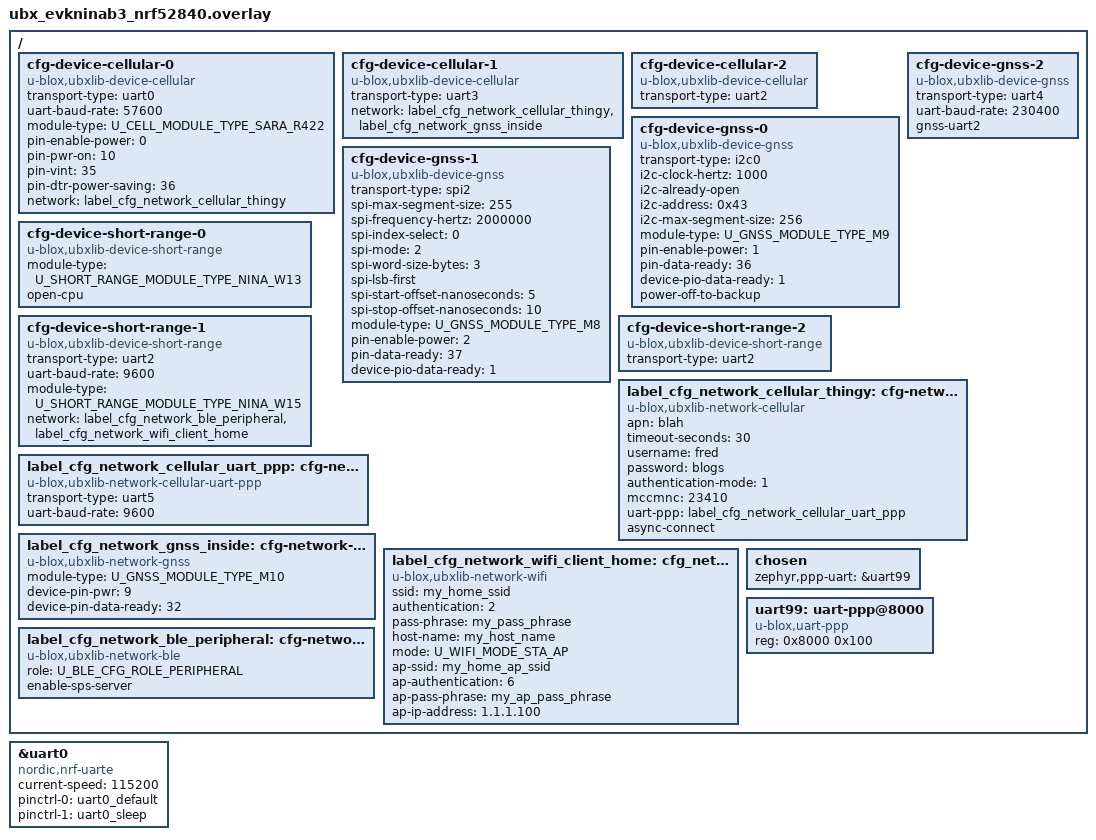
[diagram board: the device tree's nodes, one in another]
/* This configuration is used only to test setting ubxlib device and network configurations through
 * the device tree, it does not represent any real/useful settings.  The values here are checked
 * by the test zephyrPortBoardCfgBasic(); if you change a value here you must also change that test. */

/* For real settings, refer to the file of the same name in the boards/arm directory of Zephyr. */

/ {
    cfg-device-cellular-0 {
        compatible = "u-blox,ubxlib-device-cellular";
        status = "okay";
        transport-type = "uart0";
        uart-baud-rate = <57600>;
        module-type = "U_CELL_MODULE_TYPE_SARA_R422";
        pin-enable-power = <0>;
        pin-pwr-on = <10>;
        pin-vint = <35>;
        pin-dtr-power-saving = <36>;
        network = <&label_cfg_network_cellular_thingy>;
    };
    cfg-device-cellular-1 {
        compatible = "u-blox,ubxlib-device-cellular";
        status = "okay";
        transport-type = "uart3";
        network = <&label_cfg_network_cellular_thingy &label_cfg_network_gnss_inside>;
    };
    cfg-device-cellular-2 {
        compatible = "u-blox,ubxlib-device-cellular";
        status = "okay";
        transport-type = "uart2";
    };
    cfg-device-gnss-0 {
        compatible = "u-blox,ubxlib-device-gnss";
        status = "okay";
        transport-type = "i2c0";
        i2c-clock-hertz = <1000>;
        i2c-already-open;
        i2c-address = <0x43>;
        i2c-max-segment-size = <256>;
        module-type = "U_GNSS_MODULE_TYPE_M9";
        pin-enable-power = <1>;
        pin-data-ready = <36>;
        device-pio-data-ready = <1>;
        power-off-to-backup;
    };
    cfg-device-gnss-1 {
        compatible = "u-blox,ubxlib-device-gnss";
        status = "okay";
        transport-type = "spi2";
        spi-max-segment-size = <255>;
        spi-frequency-hertz = <2000000>;
        spi-index-select = <0>;
        spi-mode = <2>;
        spi-word-size-bytes = <3>;
        spi-lsb-first;
        spi-start-offset-nanoseconds = <5>;
        spi-stop-offset-nanoseconds = <10>;
        module-type = "U_GNSS_MODULE_TYPE_M8";
        pin-enable-power = <2>;
        pin-data-ready = <37>;
        device-pio-data-ready = <1>;
    };
    cfg-device-gnss-2 {
        compatible = "u-blox,ubxlib-device-gnss";
        status = "okay";
        transport-type = "uart4";
        uart-baud-rate = <230400>;
        gnss-uart2;
    };
    cfg-device-short-range-0 {
        compatible = "u-blox,ubxlib-device-short-range";
        status = "okay";
        module-type = "U_SHORT_RANGE_MODULE_TYPE_NINA_W13";
        open-cpu;
    };
    cfg-device-short-range-1 {
        compatible = "u-blox,ubxlib-device-short-range";
        status = "okay";
        transport-type = "uart2";
        uart-baud-rate = <9600>;
        module-type = "U_SHORT_RANGE_MODULE_TYPE_NINA_W15";
        network = <&label_cfg_network_ble_peripheral &label_cfg_network_wifi_client_home>;
    };
    cfg-device-short-range-2 {
        compatible = "u-blox,ubxlib-device-short-range";
        status = "okay";
        transport-type = "uart2";
    };
    label_cfg_network_cellular_thingy: cfg-network-cellular-thingy {
        compatible = "u-blox,ubxlib-network-cellular";
        apn = "blah";
        timeout-seconds = <30>;
        username = "fred";
        password = "blogs";
        authentication-mode = <1>;
        mccmnc = "23410";
        uart-ppp = <&label_cfg_network_cellular_uart_ppp>;
        async-connect;
    };
    label_cfg_network_cellular_uart_ppp: cfg-network-cellular-uart-ppp {
        compatible = "u-blox,ubxlib-network-cellular-uart-ppp";
        transport-type = "uart5";
        uart-baud-rate = <9600>;
    };
    label_cfg_network_gnss_inside: cfg-network-gnss-inside {
        compatible = "u-blox,ubxlib-network-gnss";
        module-type = "U_GNSS_MODULE_TYPE_M10";
        device-pin-pwr = <9>;
        device-pin-data-ready = <32>;
    };
    label_cfg_network_wifi_client_home: cfg_network_wifi_client_home {
        compatible = "u-blox,ubxlib-network-wifi";
        ssid = "my_home_ssid";
        authentication = <2>;
        pass-phrase = "my_pass_phrase";
        host-name = "my_host_name";
        mode = "U_WIFI_MODE_STA_AP";
        ap-ssid = "my_home_ap_ssid";
        ap-authentication = <6>;
        ap-pass-phrase = "my_ap_pass_phrase";
        ap-ip-address = "1.1.1.100";
    };
    label_cfg_network_ble_peripheral: cfg-network-ble-peripheral {
        compatible = "u-blox,ubxlib-network-ble";
        role = "U_BLE_CFG_ROLE_PERIPHERAL";
        enable-sps-server;
    };
};

&uart0 {
    compatible = "nordic,nrf-uarte";
    status = "okay";
    current-speed = <115200>;
    pinctrl-0 = <&uart0_default>;
    pinctrl-1 = <&uart0_sleep>;
    pinctrl-names = "default", "sleep";
};

/* Required for PPP-level integration with ubxlib to work */
/ { // The leading / indicates that we're in the root section
    // This chooses uart instance 99 to be the zephyr,ppp-uart that ppp.c wants
    chosen {
        zephyr,ppp-uart = &uart99;
    };

    // This creates instance 99 of a uart that we will give to zephyr,ppp-uart
    uart99: uart-ppp@8000 { // The "8000" here is irrelevant but required for Zephyr to work
        compatible = "u-blox,uart-ppp"; // The important part: this is an instance of u-blox,uart-ppp
        reg = <0x8000 0x100>; // This is irrelevant but required for Zephyr to work
        status = "okay"; // Zephyr boiler-plate
    };
};
